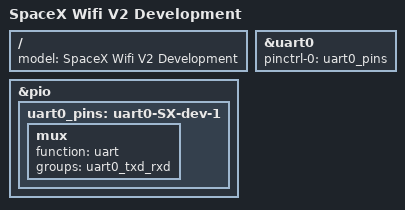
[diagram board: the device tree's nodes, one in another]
/*
 * Copyright (c) 2021 SpaceX.
 * Author: Collin Valley <collin.valley@spacex.com>
 *
 * This program is free software; you can redistribute it and/or modify
 * it under the terms of the GNU General Public License version 2 as
 * published by the Free Software Foundation.
 *
 * This program is distributed in the hope that it will be useful,
 * but WITHOUT ANY WARRANTY; without even the implied warranty of
 * MERCHANTABILITY or FITNESS FOR A PARTICULAR PURPOSE.  See the
 * GNU General Public License for more details.
 */

/dts-v1/;
#include "spacex-v2-1.dtsi"

/ {
  model = "SpaceX Wifi V2 Development";
};

&pio {
    uart0_pins: uart0-SX-dev-1 {
        mux {
            function = "uart";
            groups = "uart0_txd_rxd";
        };
    };
};

&uart0 {
    pinctrl-names = "default";
    pinctrl-0 = <&uart0_pins>;
};
